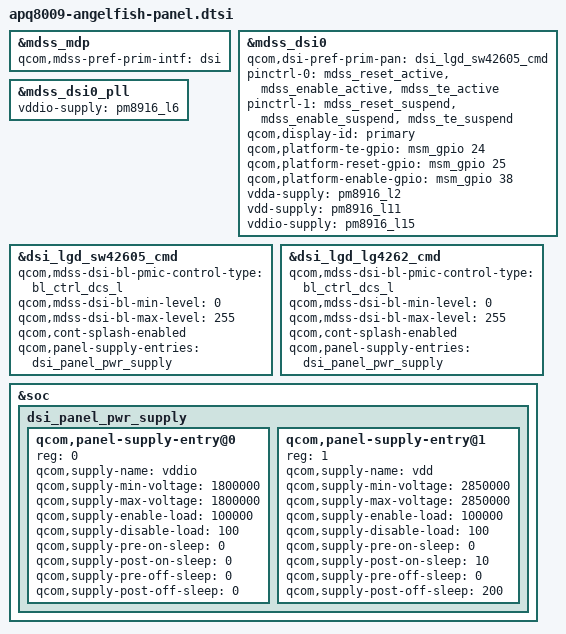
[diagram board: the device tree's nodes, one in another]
/* Copyright (c) 2016, LGE Inc. All rights reserved.
 *
 * This program is free software; you can redistribute it and/or modify
 * it under the terms of the GNU General Public License version 2 and
 * only version 2 as published by the Free Software Foundation.
 *
 * This program is distributed in the hope that it will be useful,
 * but WITHOUT ANY WARRANTY; without even the implied warranty of
 * MERCHANTABILITY or FITNESS FOR A PARTICULAR PURPOSE.  See the
 * GNU General Public License for more details.
 */

#include "dsi-panel-lgd-sw42605-360p-cmd.dtsi"
#include "dsi-panel-lgd-lg4262-480p-cmd.dtsi"

&mdss_mdp {
	qcom,mdss-pref-prim-intf = "dsi";
};

&mdss_dsi0 {
	qcom,dsi-pref-prim-pan = <&dsi_lgd_sw42605_cmd>;
	pinctrl-names = "mdss_default", "mdss_sleep";
	pinctrl-0 = <&mdss_reset_active &mdss_enable_active &mdss_te_active>;
	pinctrl-1 = <&mdss_reset_suspend &mdss_enable_suspend &mdss_te_suspend>;
	qcom,display-id = "primary";

	qcom,platform-te-gpio = <&msm_gpio 24 0>;
	qcom,platform-reset-gpio = <&msm_gpio 25 0>;
	qcom,platform-enable-gpio = <&msm_gpio 38 0>;

	vdda-supply = <&pm8916_l2>;
	vdd-supply = <&pm8916_l11>;
	vddio-supply = <&pm8916_l15>;
};

&mdss_dsi0_pll {
	vddio-supply = <&pm8916_l6>;
};

&dsi_lgd_sw42605_cmd {
	qcom,mdss-dsi-bl-pmic-control-type = "bl_ctrl_dcs_l";
	qcom,mdss-dsi-bl-min-level = <0>;
	qcom,mdss-dsi-bl-max-level = <255>;
	qcom,cont-splash-enabled;
	qcom,panel-supply-entries = <&dsi_panel_pwr_supply>;
};

&dsi_lgd_lg4262_cmd {
	qcom,mdss-dsi-bl-pmic-control-type = "bl_ctrl_dcs_l";
	qcom,mdss-dsi-bl-min-level = <0>;
	qcom,mdss-dsi-bl-max-level = <255>;
	qcom,cont-splash-enabled;
	qcom,panel-supply-entries = <&dsi_panel_pwr_supply>;
};

&soc {
	dsi_panel_pwr_supply: dsi_panel_pwr_supply {
		#address-cells = <1>;
		#size-cells = <0>;

		qcom,panel-supply-entry@0 {
			reg = <0>;
			qcom,supply-name = "vddio";
			qcom,supply-min-voltage = <1800000>;
			qcom,supply-max-voltage = <1800000>;
			qcom,supply-enable-load = <100000>;
			qcom,supply-disable-load = <100>;
			qcom,supply-pre-on-sleep = <0>;
			qcom,supply-post-on-sleep = <0>;
			qcom,supply-pre-off-sleep = <0>;
			qcom,supply-post-off-sleep = <0>;
		};

		qcom,panel-supply-entry@1 {
			reg = <1>;
			qcom,supply-name = "vdd";
			qcom,supply-min-voltage = <2850000>;
			qcom,supply-max-voltage = <2850000>;
			qcom,supply-enable-load = <100000>;
			qcom,supply-disable-load = <100>;
			qcom,supply-pre-on-sleep = <0>;
			qcom,supply-post-on-sleep = <10>;
			qcom,supply-pre-off-sleep = <0>;
			qcom,supply-post-off-sleep = <200>;

		};
	};
};
